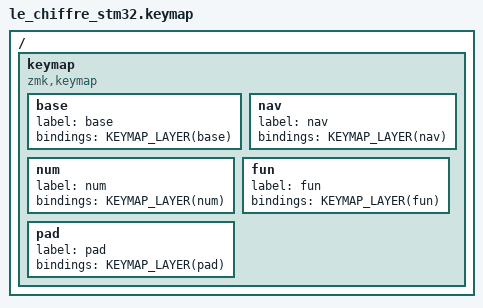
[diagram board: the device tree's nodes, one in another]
/*
 * Le Chiffre 36 (STM32; sporkus) — thin keymap. Vendored HWv2 STM32F072 board in
 * boards/shields/le_chiffre_stm32/, USB only. 3x5 core + 3 thumbs/hand (the board's
 * 36-key transform), so it reuses the shared adapter geom_3x5_3.h. Encoder disabled.
 * All content lives in config/shared/.
 */

#include <behaviors.dtsi>
#include <dt-bindings/zmk/keys.h>
#include <dt-bindings/zmk/bt.h>
#include <dt-bindings/zmk/outputs.h>

#include "geometry/geom_3x5_3.h"

#include "shared/keys_de.h"
#include "shared/settings.dtsi"
#include "shared/behaviors.dtsi"
#include "shared/macros.dtsi"
#include "shared/combos.dtsi"
#include "shared/core_blocks.dtsi"

/ {
    keymap {
        compatible = "zmk,keymap";

        base { label = "base"; bindings = <KEYMAP_LAYER(base)>; };
        nav  { label = "nav";  bindings = <KEYMAP_LAYER(nav)>;  };
        num  { label = "num";  bindings = <KEYMAP_LAYER(num)>;  };
        fun  { label = "fun";  bindings = <KEYMAP_LAYER(fun)>;  };
        pad  { label = "pad";  bindings = <KEYMAP_LAYER(pad)>;  };
    };
};
